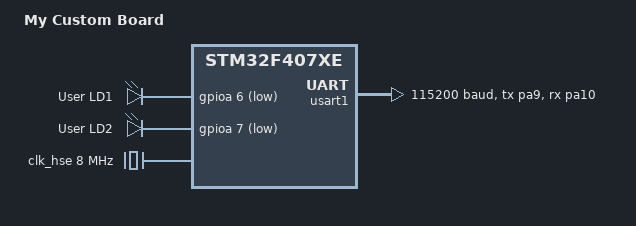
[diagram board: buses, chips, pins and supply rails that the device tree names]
/*
 * Copyright (c) 2026 Your Company
 * SPDX-License-Identifier: Apache-2.0
 */

/dts-v1/;
#include <st/f4/stm32f407Xe.dtsi>
#include <st/f4/stm32f407v(e-g)tx-pinctrl.dtsi>

/ {
	model = "My Custom Board";
	compatible = "mycompany,our-board";

	chosen {
		zephyr,console = &usart1;
		zephyr,shell-uart = &usart1;
		zephyr,sram = &sram0;
		zephyr,flash = &flash0;
		zephyr,dtcm = &ccm0;
	};

	leds {
		compatible = "gpio-leds";

		green_led_1: led_1 {
			gpios = <&gpioa 6 GPIO_ACTIVE_LOW>;
			label = "User LD1";
		};

		green_led_2: led_2 {
			gpios = <&gpioa 7 GPIO_ACTIVE_LOW>;
			label = "User LD2";
		};
	};

	aliases {
		led0 = &green_led_1;
		led1 = &green_led_2;
	};
};

/* --- CLOCK AND RCC CONFIGURATION --- */
&clk_lsi {
	status = "okay";
};

&clk_hse {
	clock-frequency = <DT_FREQ_M(8)>;
	status = "okay";
};

&pll {
	div-m = <8>;
	mul-n = <336>;
	div-p = <2>;
	div-q = <7>;
	clocks = <&clk_hse>;
	status = "okay";
};

&rcc {
	clocks = <&pll>;
	clock-frequency = <DT_FREQ_M(168)>;
	ahb-prescaler = <1>;
	apb1-prescaler = <4>;
	apb2-prescaler = <2>;
};

/* --- PRIMARY SYSTEM SERIAL CONSOLE --- */
&usart1 {
	pinctrl-0 = <&usart1_tx_pa9 &usart1_rx_pa10>;
	pinctrl-names = "default";
	current-speed = <115200>;
	status = "okay";
};
